# RP2040 register map
Vendor: Raspberry Pi; File version: 0.1
CPU: CM0PLUS r0p1, little endian, MPU, no FPU, VTOR, 2 interrupt priority bits, 26 interrupts
Registers are 32-bit, read-write, reset 0x0 unless marked. A register's access mark holds for its fields unless they carry their own. Offsets are from the block's base; [hi:lo] are bit positions.

## XIP_CTRL — QSPI flash execute-in-place block
Base 0x14000000
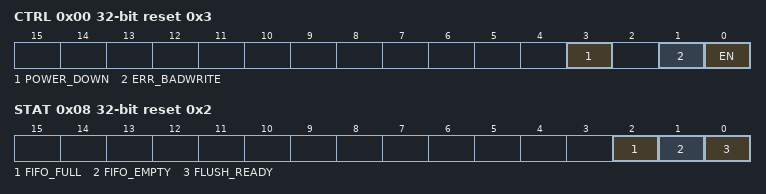
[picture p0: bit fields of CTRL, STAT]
0x00 CTRL reset 0x3 — Cache control
  [3] POWER_DOWN — When 1, the cache memories are powered down. They retain state, but can not be accessed. This reduces static power dissipation. Writing 1 to this bit forces CTRL_EN to 0, i.e. the cache cannot be enabled when powered down. Cache-as-SRAM accesses will produce a bus error response when the cache is powered down.
  [1] ERR_BADWRITE — When 1, writes to any alias other than 0x0 (caching, allocating) will produce a bus fault. When 0, these writes are silently ignored. In either case, writes to the 0x0 alias will deallocate on tag match, as usual.
  [0] EN — When 1, enable the cache. When the cache is disabled, all XIP accesses will go straight to the flash, without querying the cache. When enabled, cacheable XIP accesses will query the cache, and the flash will not be accessed if the tag matches and the valid bit is set. . If the cache is enabled, cache-as-SRAM accesses have no effect on the cache data RAM, and will produce a bus error response.
0x04 FLUSH — Cache Flush control
  [0] FLUSH write-clears — Write 1 to flush the cache. This clears the tag memory, but the data memory retains its contents. (This means cache-as-SRAM contents is not affected by flush or reset.). Reading will hold the bus (stall the processor) until the flush completes. Alternatively STAT can be polled until completion.
0x08 STAT ro reset 0x2 — Cache Status
  [2] FIFO_FULL — When 1, indicates the XIP streaming FIFO is completely full. The streaming FIFO is 2 entries deep, so the full and empty flag allow its level to be ascertained.
  [1] FIFO_EMPTY — When 1, indicates the XIP streaming FIFO is completely empty.
  [0] FLUSH_READY — Reads as 0 while a cache flush is in progress, and 1 otherwise. The cache is flushed whenever the XIP block is reset, and also when requested via the FLUSH register.
0x0C CTR_HIT write-1-clears — Cache Hit counter. A 32 bit saturating counter that increments upon each cache hit, i.e. when an XIP access is serviced directly from cached data. Write any value to clear.
0x10 CTR_ACC write-1-clears — Cache Access counter. A 32 bit saturating counter that increments upon each XIP access, whether the cache is hit or not. This includes noncacheable accesses. Write any value to clear.
0x14 STREAM_ADDR — FIFO stream address
  [31:2] STREAM_ADDR — The address of the next word to be streamed from flash to the streaming FIFO. Increments automatically after each flash access. Write the initial access address here before starting a streaming read.
0x18 STREAM_CTR — FIFO stream control
  [21:0] STREAM_CTR — Write a nonzero value to start a streaming read. This will then progress in the background, using flash idle cycles to transfer a linear data block from flash to the streaming FIFO. Decrements automatically (1 at a time) as the stream progresses, and halts on reaching 0. Write 0 to halt an in-progress stream, and discard any in-flight read, so that a new stream can immediately be started (after draining the FIFO and reinitialising STREAM_ADDR)
0x1C STREAM_FIFO ro — FIFO stream data. Streamed data is buffered here, for retrieval by the system DMA. This FIFO can also be accessed via the XIP_AUX slave, to avoid exposing the DMA to bus stalls caused by other XIP traffic.

## SYSINFO
Base 0x40000000
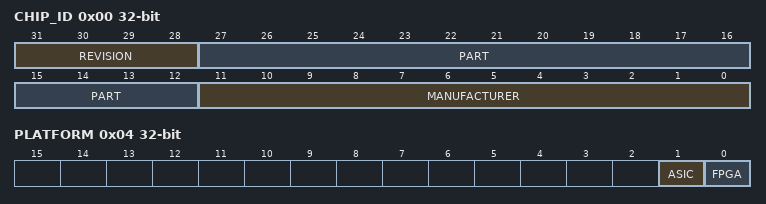
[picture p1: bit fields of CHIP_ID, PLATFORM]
0x00 CHIP_ID ro — JEDEC JEP-106 compliant chip identifier.
  [31:28] REVISION, [27:12] PART, [11:0] MANUFACTURER
0x04 PLATFORM ro — Platform register. Allows software to know what environment it is running in.
  [1] ASIC, [0] FPGA
0x40 GITREF_RP2040 ro — Git hash of the chip source. Used to identify chip version.

## Notices in the file
Copyright (c) 2020 Raspberry Pi (Trading) Ltd.
SPDX-License-Identifier: BSD-3-Clause
